# ESP32S31_RADIO register map
Vendor: Espressif; Series: ESP32-S31; File version: 3.52
Registers are 32-bit, read-write, no defined reset value unless marked. A register's access mark holds for its fields unless they carry their own. Offsets are from the block's base; [hi:lo] are bit positions; {n}, {i} and the like mark numbered series.

## WIFI_MAC_COEX_INIT — Complete COEX/PTI tail of hal_init and complete setter leaves. PTI values remain platform-supplied because the coexistence table may be changed at runtime.
Base 0x201042FC
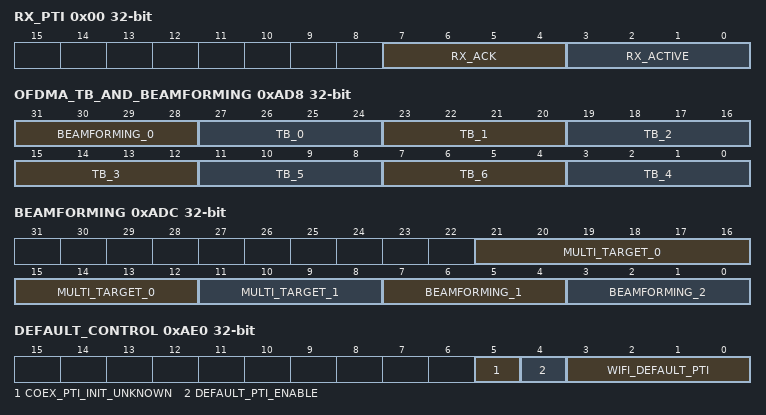
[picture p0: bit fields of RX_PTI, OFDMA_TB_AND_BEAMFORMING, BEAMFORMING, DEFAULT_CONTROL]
0x00 RX_PTI — Complete hal_init replaces RX-active and RX-ACK nibbles through two separate setter RMWs.
  [7:4] RX_ACK — PTI returned for event three and published by hal_set_rx_ack_pti.
  [3:0] RX_ACTIVE — Complete hal_init passes zero to hal_set_rx_active_pti.
0xAD8 OFDMA_TB_AND_BEAMFORMING — Seven trigger-based PTIs and one beamforming PTI, each published through a separate fresh-read RMW by complete setters.
  [31:28] BEAMFORMING_0, [27-4n:24-4n] TB_{n} (n=0..3), [11:8] TB_5, [7:4] TB_6, [3:0] TB_4
0xADC BEAMFORMING — Two ordinary and two multi-target beamforming PTI fields, programmed through four separate fresh-read RMWs.
  [21:12] MULTI_TARGET_0 — Complete hal_set_beamf_mt_pti replaces bits 21:12 with its unmasked first argument; cold PTI values occupy only the low nibble of this ten-bit field.
  [11:8] MULTI_TARGET_1
  [7:4] BEAMFORMING_1
  [3:0] BEAMFORMING_2
0xAE0 DEFAULT_CONTROL — Common COEX enable/default PTI word updated by three separate setter RMWs.
  [5] COEX_PTI_INIT_UNKNOWN — Set by complete hal_coex_pti_init.
  [4] DEFAULT_PTI_ENABLE — Set by hal_coex_enable_default_pti(1).
  [3:0] WIFI_DEFAULT_PTI — PTI returned for event fifteen.

## WIFI_MAC_ANTENNA_INIT — Complete hal_attenna_init transaction. The misspelled vendor symbol first visits eight reverse-stride queue/vector words, then updates one common word.
Base 0x201042B0
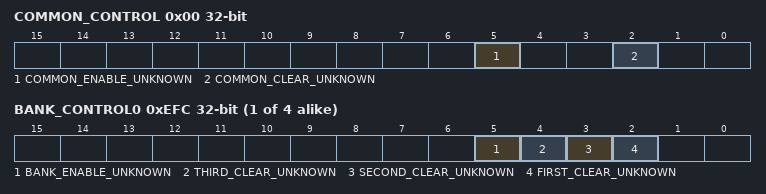
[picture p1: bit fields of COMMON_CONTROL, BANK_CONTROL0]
0x00 COMMON_CONTROL — Complete leaf clears bit 2, then sets bit 5 through a separate fresh-read RMW.
  [5] COMMON_ENABLE_UNKNOWN — Set by the final RMW of the complete leaf.
  [2] COMMON_CLEAR_UNKNOWN — Cleared by the penultimate RMW of the complete leaf.
{0xEFC+0x7C*i} BANK_CONTROL{i} (i=0..3) — Lower four unique words of the eight-word antenna traversal, at 0x201051ac..0x20105320. The upper four words are the canonical WIFI_MAC_TX_QUEUE_VECTOR.LENGTH_CONTROL array, whose decoded antenna fields occupy the same bits.
  [5] BANK_ENABLE_UNKNOWN — Set in the middle RMW of each word in the second reverse traversal.
  [4] THIRD_CLEAR_UNKNOWN — Cleared in the third RMW of each word in the second reverse traversal.
  [3] SECOND_CLEAR_UNKNOWN — Cleared in the first RMW of each word in the second reverse traversal.
  [2] FIRST_CLEAR_UNKNOWN — Cleared for all eight words in the first reverse traversal.

## WIFI_MAC_TSF_STATUS — Station TSF activity status recovered from the complete no-call hal_is_sta_tsf_active leaf. The instruction body proves the address and bit geometry but not the hardware transition rules.
Base 0x2010D80C
0x00 STATUS ro — Complete hal_is_sta_tsf_active returns bit zero.
  [0] STATION_ACTIVE
0x04 WAKEUP_SIGNAL_CLEAR — Complete pm_clear_wakeup_signal sets bit zero before invoking two externally supplied synchronization callbacks; hardware clear behavior remains unknown.
  [0] CLEAR

## WIFI_MAC_STA_TBTT_TARGET — Station TBTT target word recovered from complete hal_set_sta_tbtt. The low 26-bit packing from the supplied 64-bit TSF value is exact; the hardware counter unit remains unnamed.
Base 0x2010D82C
0x00 TARGET — Complete hal_set_sta_tbtt replaces bits 25:0 with bits 35:10 of the supplied station TSF value and preserves the high six bits.
  [25:0] TSF_BITS_35_10

## WIFI_MAC_STA_TSF_LOAD — Shared station TSF load and coherent snapshot transaction.
Base 0x2010D814
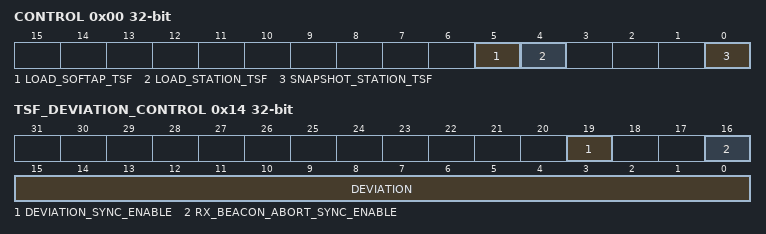
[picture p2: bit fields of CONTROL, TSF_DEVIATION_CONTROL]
0x00 CONTROL — Complete hal_set_sta_tsf asserts bit four after writing both station TSF value words; the SoftAP path of complete hal_mac_tsf_reset asserts bit five after clearing both shared TSF value words; complete hal_get_sta_tsf sets then clears bit zero around its snapshot reads.
  [5] LOAD_SOFTAP_TSF — SoftAP TSF load request asserted after the two zero-value writes by the arg0=0 path of complete hal_mac_tsf_reset.
  [4] LOAD_STATION_TSF — Station TSF load request asserted by the final fresh-read RMW in hal_set_sta_tsf.
  [0] SNAPSHOT_STATION_TSF — Complete hal_get_sta_tsf sets this bit before either station TSF word is sampled and clears it after the optional reads.
0x04 VALUE_LOW wo — Low 32 bits written first by complete hal_set_sta_tsf.
  [31:0] VALUE
0x08 VALUE_HIGH wo — High 32 bits written second by complete hal_set_sta_tsf.
  [31:0] VALUE
0x0C SNAPSHOT_LOW ro — Coherently latched low 32 bits conditionally read by complete hal_get_sta_tsf.
  [31:0] VALUE
0x10 SNAPSHOT_HIGH ro — Coherently latched high 32 bits conditionally read by complete hal_get_sta_tsf.
  [31:0] VALUE
0x14 TSF_DEVIATION_CONTROL — Complete ROM leaves independently replace the TSF deviation value and set two synchronization controls; omitted bits remain semantically unknown.
  [19] DEVIATION_SYNC_ENABLE, [16] RX_BEACON_ABORT_SYNC_ENABLE, [15:0] DEVIATION
